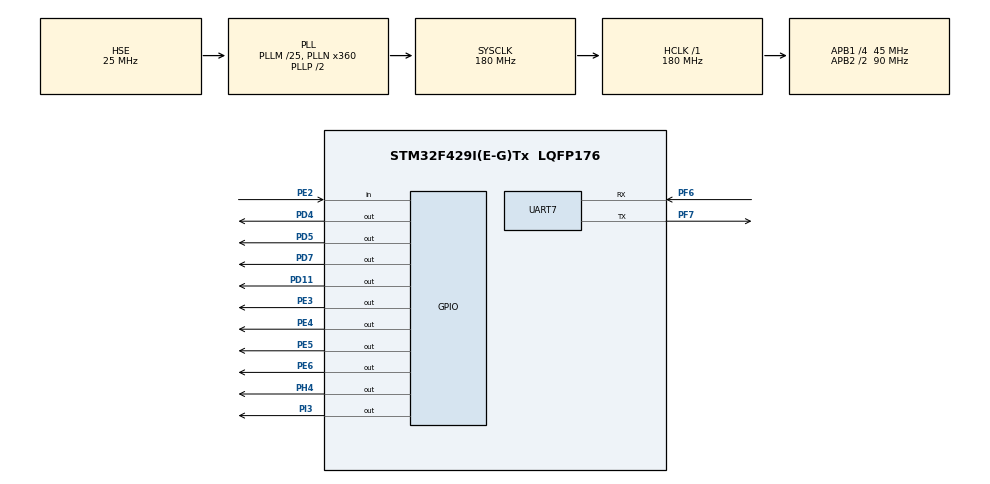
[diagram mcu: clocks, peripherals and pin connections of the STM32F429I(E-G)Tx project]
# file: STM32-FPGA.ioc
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Dma.Request0=UART7_RX
Dma.Request1=UART7_TX
Dma.UART7_RX.0.Direction=DMA_PERIPH_TO_MEMORY
Dma.UART7_RX.0.FIFOMode=DMA_FIFOMODE_DISABLE
Dma.UART7_RX.0.Instance=DMA1_Stream3
Dma.UART7_RX.0.MemDataAlignment=DMA_MDATAALIGN_BYTE
Dma.UART7_RX.0.MemInc=DMA_MINC_ENABLE
Dma.UART7_RX.0.Mode=DMA_NORMAL
Dma.UART7_RX.0.PeriphDataAlignment=DMA_PDATAALIGN_BYTE
Dma.UART7_RX.0.PeriphInc=DMA_PINC_DISABLE
Dma.UART7_RX.0.Priority=DMA_PRIORITY_LOW
Dma.UART7_TX.1.Direction=DMA_MEMORY_TO_PERIPH
Dma.UART7_TX.1.FIFOMode=DMA_FIFOMODE_DISABLE
Dma.UART7_TX.1.Instance=DMA1_Stream1
Dma.UART7_TX.1.MemDataAlignment=DMA_MDATAALIGN_BYTE
Dma.UART7_TX.1.MemInc=DMA_MINC_ENABLE
Dma.UART7_TX.1.Mode=DMA_NORMAL
Dma.UART7_TX.1.PeriphDataAlignment=DMA_PDATAALIGN_BYTE
Dma.UART7_TX.1.PeriphInc=DMA_PINC_DISABLE
Dma.UART7_TX.1.Priority=DMA_PRIORITY_LOW
FREERTOS.Tasks01=mainTask,0,128,Start_mainTask,As weak,NULL,Dynamic,NULL,NULL;uartTask,-2,128,Start_uartTask,As weak,NULL,Dynamic,NULL,NULL;spiTask,-2,128,Start_spiTask,As weak,NULL,Dynamic,NULL,NULL
Mcu.Family=STM32F4
Mcu.Name=STM32F429I(E-G)Tx
Mcu.Package=LQFP176
NVIC.DMA1_Stream1_IRQn=true\:5\:0\:false\:false\:true\:true\:false\:true\:true
NVIC.DMA1_Stream3_IRQn=true\:5\:0\:false\:false\:true\:true\:false\:true\:true
NVIC.PriorityGroup=NVIC_PRIORITYGROUP_4
NVIC.UART7_IRQn=true\:5\:0\:false\:false\:true\:true\:true\:true\:true
PA13.Mode=Serial_Wire
PA13.Signal=SYS_JTMS-SWDIO
PA14.Mode=Serial_Wire
PA14.Signal=SYS_JTCK-SWCLK
PB3.Signal=SPI1_SCK
PD11.Signal=GPIO_Output
PD4.Signal=GPIO_Output
PD5.Signal=GPIO_Output
PD7.Signal=GPIO_Output
PE2.Signal=GPIO_Input
PE3.Signal=GPIO_Output
PE4.Signal=GPIO_Output
PE5.Signal=GPIO_Output
PE6.Signal=GPIO_Output
PF6.Mode=Asynchronous
PF6.Signal=UART7_RX
PF7.Mode=Asynchronous
PF7.Signal=UART7_TX
PH0/OSC_IN.Mode=HSE-External-Oscillator
PH0/OSC_IN.Signal=RCC_OSC_IN
PH1/OSC_OUT.Mode=HSE-External-Oscillator
PH1/OSC_OUT.Signal=RCC_OSC_OUT
PH4.Signal=GPIO_Output
PI3.Signal=GPIO_Output
ProjectManager.HeapSize=0x400
ProjectManager.StackSize=0x400
ProjectManager.TargetToolchain=MDK-ARM V5.32
RCC.48MHZClocksFreq_Value=45000000
RCC.AHBFreq_Value=180000000
RCC.APB1CLKDivider=RCC_HCLK_DIV4
RCC.APB1Freq_Value=45000000
RCC.APB1TimFreq_Value=90000000
RCC.APB2CLKDivider=RCC_HCLK_DIV2
RCC.APB2Freq_Value=90000000
RCC.APB2TimFreq_Value=180000000
RCC.CortexFreq_Value=180000000
RCC.HCLKFreq_Value=180000000
RCC.HSE_VALUE=25000000
RCC.HSI_VALUE=16000000
RCC.LSE_VALUE=32768
RCC.PLLM=25
RCC.PLLN=360
RCC.PLLQ=8
RCC.PLLSourceVirtual=RCC_PLLSOURCE_HSE
RCC.SYSCLKFreq_VALUE=180000000
RCC.SYSCLKSource=RCC_SYSCLKSOURCE_PLLCLK
RCC.VCOOutputFreq_Value=360000000
UART7.Parity=PARITY_NONE
UART7.VirtualMode=Asynchronous
UART7.WordLength=WORDLENGTH_8B
VP_FREERTOS_VS_CMSIS_V1.Mode=CMSIS_V1
board=custom

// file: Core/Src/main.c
/* USER CODE BEGIN Header */
/**
  ******************************************************************************
  * @file           : main.c
  * @brief          : Main program body
  ******************************************************************************
  * @attention
  *
  * Copyright (c) 2026 STMicroelectronics.
  * All rights reserved.
  *
  * This software is licensed under terms that can be found in the LICENSE file
  * in the root directory of this software component.
  * If no LICENSE file comes with this software, it is provided AS-IS.
  *
  ******************************************************************************
  */
/* USER CODE END Header */
#include "main.h"
#include "cmsis_os.h"
#include "dma.h"
#include "usart.h"
#include "gpio.h"

/* USER CODE BEGIN PV */
	uint8_t ch[] = {0};
/* USER CODE END PV */

void SystemClock_Config(void);
void MX_FREERTOS_Init(void);

int main(void)
{

  /* MCU Configuration--------------------------------------------------------*/

  /* Reset of all peripherals, Initializes the Flash interface and the Systick. */
  HAL_Init();

  /* Configure the system clock */
  SystemClock_Config();

  /* Initialize all configured peripherals */
  MX_GPIO_Init();
  MX_DMA_Init();
  MX_UART7_Init();

  /* Call init function for freertos objects (in cmsis_os2.c) */
  MX_FREERTOS_Init();

  /* Start scheduler */
  osKernelStart();

  /* We should never get here as control is now taken by the scheduler */

  /* Infinite loop */
  while (1)
  {

  }
}

void SystemClock_Config(void)
{
  RCC_OscInitTypeDef RCC_OscInitStruct = {0};
  RCC_ClkInitTypeDef RCC_ClkInitStruct = {0};

  /** Configure the main internal regulator output voltage
  */
  __HAL_RCC_PWR_CLK_ENABLE();
  __HAL_PWR_VOLTAGESCALING_CONFIG(PWR_REGULATOR_VOLTAGE_SCALE1);

  /** Initializes the RCC Oscillators according to the specified parameters
  * in the RCC_OscInitTypeDef structure.
  */
  RCC_OscInitStruct.OscillatorType = RCC_OSCILLATORTYPE_HSE;
  RCC_OscInitStruct.HSEState = RCC_HSE_ON;
  RCC_OscInitStruct.PLL.PLLState = RCC_PLL_ON;
  RCC_OscInitStruct.PLL.PLLSource = RCC_PLLSOURCE_HSE;
  RCC_OscInitStruct.PLL.PLLM = 25;
  RCC_OscInitStruct.PLL.PLLN = 360;
  RCC_OscInitStruct.PLL.PLLP = RCC_PLLP_DIV2;
  RCC_OscInitStruct.PLL.PLLQ = 8;
  if (HAL_RCC_OscConfig(&RCC_OscInitStruct) != HAL_OK)
  {
    Error_Handler();
  }

  /** Activate the Over-Drive mode
  */
  if (HAL_PWREx_EnableOverDrive() != HAL_OK)
  {
    Error_Handler();
  }

  /** Initializes the CPU, AHB and APB buses clocks
  */
  RCC_ClkInitStruct.ClockType = RCC_CLOCKTYPE_HCLK|RCC_CLOCKTYPE_SYSCLK
                              |RCC_CLOCKTYPE_PCLK1|RCC_CLOCKTYPE_PCLK2;
  RCC_ClkInitStruct.SYSCLKSource = RCC_SYSCLKSOURCE_PLLCLK;
  RCC_ClkInitStruct.AHBCLKDivider = RCC_SYSCLK_DIV1;
  RCC_ClkInitStruct.APB1CLKDivider = RCC_HCLK_DIV4;
  RCC_ClkInitStruct.APB2CLKDivider = RCC_HCLK_DIV2;

  if (HAL_RCC_ClockConfig(&RCC_ClkInitStruct, FLASH_LATENCY_5) != HAL_OK)
  {
    Error_Handler();
  }
}

void Error_Handler(void)
{
  __disable_irq();
  while (1)
  {
  }
}

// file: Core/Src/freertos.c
/* USER CODE BEGIN Header */
/**
  ******************************************************************************
  * File Name          : freertos.c
  * Description        : Code for freertos applications
  ******************************************************************************
  * @attention
  *
  * Copyright (c) 2026 STMicroelectronics.
  * All rights reserved.
  *
  * This software is licensed under terms that can be found in the LICENSE file
  * in the root directory of this software component.
  * If no LICENSE file comes with this software, it is provided AS-IS.
  *
  ******************************************************************************
  */
/* USER CODE END Header */

#include "FreeRTOS.h"
#include "task.h"
#include "main.h"
#include "cmsis_os.h"

/* USER CODE BEGIN Includes */
#include "dma.h"
#include "usart.h"
/* USER CODE END Includes */

/* USER CODE BEGIN Variables */
	uint8_t test = 0;
/* USER CODE END Variables */
osThreadId mainTaskHandle;
osThreadId uartTaskHandle;
osThreadId spiTaskHandle;

void Start_mainTask(void const * argument);
void Start_uartTask(void const * argument);
void Start_spiTask(void const * argument);

void MX_FREERTOS_Init(void); /* (MISRA C 2004 rule 8.1) */

/* GetIdleTaskMemory prototype (linked to static allocation support) */
void vApplicationGetIdleTaskMemory( StaticTask_t **ppxIdleTaskTCBBuffer, StackType_t **ppxIdleTaskStackBuffer, uint32_t *pulIdleTaskStackSize );

/* USER CODE BEGIN GET_IDLE_TASK_MEMORY */
static StaticTask_t xIdleTaskTCBBuffer;
static StackType_t xIdleStack[configMINIMAL_STACK_SIZE];

void vApplicationGetIdleTaskMemory( StaticTask_t **ppxIdleTaskTCBBuffer, StackType_t **ppxIdleTaskStackBuffer, uint32_t *pulIdleTaskStackSize )
{
  *ppxIdleTaskTCBBuffer = &xIdleTaskTCBBuffer;
  *ppxIdleTaskStackBuffer = &xIdleStack[0];
  *pulIdleTaskStackSize = configMINIMAL_STACK_SIZE;
  /* place for user code */
}
/* USER CODE END GET_IDLE_TASK_MEMORY */

void MX_FREERTOS_Init(void) {

  /* Create the thread(s) */
  /* definition and creation of mainTask */
  osThreadDef(mainTask, Start_mainTask, osPriorityNormal, 0, 128);
  mainTaskHandle = osThreadCreate(osThread(mainTask), NULL);

  /* definition and creation of uartTask */
  osThreadDef(uartTask, Start_uartTask, osPriorityLow, 0, 128);
  uartTaskHandle = osThreadCreate(osThread(uartTask), NULL);

  /* definition and creation of spiTask */
  osThreadDef(spiTask, Start_spiTask, osPriorityLow, 0, 128);
  spiTaskHandle = osThreadCreate(osThread(spiTask), NULL);

}

__weak void Start_mainTask(void const * argument)
{
  /* USER CODE BEGIN Start_mainTask */
  /* Infinite loop */
  for(;;)
  {
    osDelay(500);
  }
  /* USER CODE END Start_mainTask */
}

__weak void Start_uartTask(void const * argument)
{
  for(;;)
  {
    osDelay(1);
  }
}

__weak void Start_spiTask(void const * argument)
{
  for(;;)
  {
    osDelay(1);
  }
}
